# ET6801 register map
Vendor: ETMCU Inc.; File version: v0.0.1
CPU: CM7 r2p1, little endian, MPU, FPU, I-cache, D-cache, ITCM, DTCM, 4 interrupt priority bits
Registers are 32-bit, read-write, reset 0x0 unless marked. A register's access mark holds for its fields unless they carry their own. Offsets are from the block's base; [hi:lo] are bit positions; {n}, {i} and the like mark numbered series.

## SPI0 — Provide an overview of the purpose and functionality of the peripheral: SPI_DWC_ssi
Base 0x4050B000
Same registers: SPI1 0x4050C000, SPI2 0x4050D000, SPI3 0x4050E000
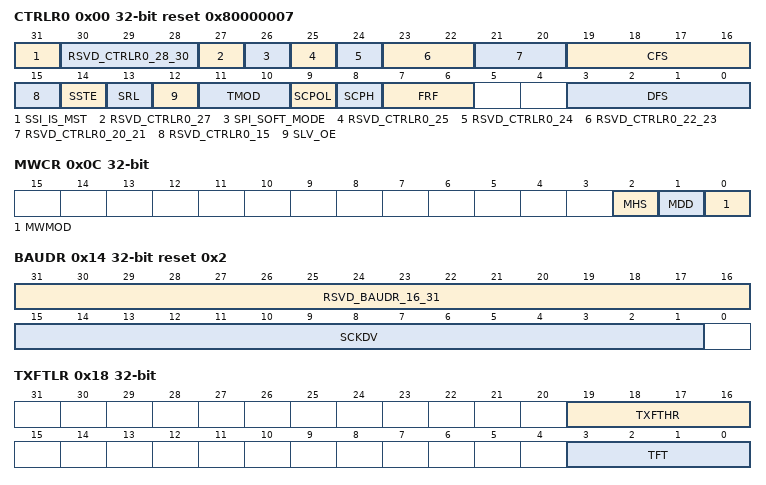
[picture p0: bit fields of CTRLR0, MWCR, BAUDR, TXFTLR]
0x00 CTRLR0 reset 0x80000007
  [31] SSI_IS_MST — This field selects if DWC_ssi is working in Controller or Target mode
  [30:28] RSVD_CTRLR0_28_30 ro — Reserved bits - read as zero
  [27] RSVD_CTRLR0_27 ro — Reserved bits - read as zero
  [26] SPI_SOFT_MODE — 0：ss_n片选信号随状态机变化 1：可使ss_n片选信号不随状态机变化，以满足burst传输模式下数据等待时ss_n片选信号持续有效。spim_soft_mode寄存器复位默认状态为0
  [25] RSVD_CTRLR0_25 ro — Reserved bits - read as zero
  [24] RSVD_CTRLR0_24 ro — Reserved bits - read as zero
  [23:22] RSVD_CTRLR0_22_23 ro — Reserved bits - read as zero
  [21:20] RSVD_CTRLR0_20_21 ro — Reserved bits - read as zero
  [19:16] CFS — Control Frame Size. Selects the length of the control word for the Microwire frame format.
  [15] RSVD_CTRLR0_15 ro — Reserved bits - read as zero
  [14] SSTE — Target Select Toggle Enable. While operating in SPI mode with clock phase (SCPH) set to 0, this register controls the behavior of the chip select line (ss_*_n) between data frames.
  [13] SRL — Shift Register Loop. Used for testing purposes only. When internally active, connects the transmit shift register output to the receive shift register input. Can be used in both serial-target and serial-controller modes. When the DWC_ssi is configured as a target in loopback mode, the ss_in_n and ssi_clk signals must be provided by an external source. In this mode, the target cannot generate these signals because there is nothing to which to loop back.
  [12] SLV_OE — Target Output Enable. Relevant only when the DWC_ssi is configured as a serial-target device. When configured as a serial controller, this bit field has no functionality. This bit enables or disables the setting of the ssi_oe_n output from the DWC_ssi serial target. When SLV_OE = 1, the ssi_oe_n output can never be active. When the ssi_oe_n output controls the tri-state buffer on the txd output from the target, a high impedance state is always present on the target txd output when SLV_OE = 1. This is useful when the controller transmits in broadcast mode (controller transmits data to all target devices). Only one target may respond with data on the controller rxd line. This bit is enabled after reset and must be disabled by software (when broadcast mode is used), if you do not want this device to respond with data. When SSIC_SLV_SPI_MODE is set to 1 and SPI is programmed to work in Enhanced SPI mode, then for correct operation this bit should be programmed to 0.
  [11:10] TMOD — Transfer Mode. Selects the mode of transfer for serial communication. This field does not affect the transfer duplicity. Only indicates whether the receive or transmit data are valid. In transmit-only mode, data received from the external device is not valid and is not stored in the receive FIFO memory; it is overwritten on the next transfer. In receive-only mode, transmitted data are not valid. After the first write to the transmit FIFO, the same word is retransmitted for the duration of the transfer. In transmit-and-receive mode, both transmit and receive data are valid. The transfer continues until the transmit FIFO is empty. Data received from the external device are stored into the receive FIFO memory, where it can be accessed by the host processor.
  [9] SCPOL — Serial Clock Polarity. Valid when the frame format (FRF) is set to Motorola SPI. Used to select the polarity of the inactive serial clock, which is held inactive when the DWC_ssi controller is not actively transferring data on the serial bus.
  [8] SCPH — Serial Clock Phase. Valid when the frame format (FRF) is set to Motorola SPI. The serial clock phase selects the relationship of the serial clock with the chip select signal. When SCPH = 0, data are captured on the first edge of the serial clock. When SCPH = 1, the serial clock starts toggling one cycle after the chip select line is activated, and data are captured on the second edge of the serial clock.
  [7:6] FRF — Frame Format. Selects which serial protocol transfers the data.
  [3:0] DFS — Data Frame Size. Selects the data frame length. When the data frame size is programmed to be less than 16 bits, the receive data is automatically right-justified by the receive logic, with the upper bits of the receive FIFO zero-padded. You must right-justify transmit data before writing into the transmit FIFO. The transmit logic ignores the upper unused bits when transmitting the data. Note: When SSIC_SPI_MODE is set to "Dual", "Quad" or "Octal" mode and SPI_FRF is not set to 2'b00: - DFS value must be a multiple of 2 if SPI_FRF = 01 - DFS value must be multiple of 4 if SPI_FRF = 10 - DFS value must be multiple of 8 if SPI_FRF = 11
0x04 CTRLR1
  [15:0] NDF — Number of Data Frames. When TMOD = 10 or TMOD = 11 , this register field sets the number of data frames to be continuously received by the DWC_ssi. The DWC_ssi continues to receive serial data until the number of data frames received is equal to this register value plus 1, which enables you to receive up to 256 KB of data in a continuous transfer. When SPI_CTRLR0.CLK_STRETCH_EN=1 and TMOD = 01, this register field sets the number of data frames to be continuously transmitted by DWC_ssi. If the Transmit FIFO goes empty in-between, DWC_ssi masks the serial clock (sclk_out) and wait for rest of the data until the programmed amount of frames are transferred successfully. When the DWC_ssi is configured as a serial target, the transfer continues for as long as the target is selected. Therefore, this register serves no purpose and is not present when the DWC_ssi is configured as a serial target.
0x08 SSIENR
  [0] SSIC_EN — SSI Enable. Enables and disables all DWC_ssi operations. When disabled, all serial transfers are halted immediately. Transmit and receive FIFO buffers are cleared when the device is disabled. It is impossible to program some of the DWC_ssi control registers when enabled. When disabled, the ssi sleep output is set (after delay) to inform the system that it is safe to remove the ssi_clk, thus saving power consumption in the system.
0x0C MWCR
  [2] MHS — Microwire Handshaking. Relevant only when the DWC_ssi is configured as a serial-controller device. When configured as a serial target, this bit field has no functionality. Used to enable and disable the busy/ready handshaking interface for the Microwire protocol. When enabled, the DWC_ssi checks for a ready status from the target target, after the transfer of the last data/control bit, before clearing the BUSY status in the SR register.
  [1] MDD — Microwire Control. Defines the direction of the data word when the Microwire serial protocol is used. When this bit is set to 0, the data word is received by the DWC_ssi MacroCell from the external serial device. When this bit is set to 1, the data word is transmitted from the DWC_ssi MacroCell to the external serial device.
  [0] MWMOD — Microwire Transfer Mode. Defines whether the Microwire transfer is sequential or non-sequential. When sequential mode is used, only one control word is needed to transmit or receive a block of data words. When non-sequential mode is used, there must be a control word for each data word that is transmitted or received.
0x10 SER
  [0] SER — Chip Select Enable Flag. Each bit in this register corresponds to a chip select line (ss_x_n) from the DWC_ssi controller. When a bit in this register is set (1), the corresponding chip select line from the controller is activated when a serial transfer begins. It should be noted that setting or clearing bits in this register have no effect on the corresponding chip select outputs until a transfer is started. Before beginning a transfer, you should enable the bit in this register that corresponds to the target device with which the controller wants to communicate. When not operating in broadcast mode, only one bit in this field should be set.
0x14 BAUDR reset 0x2
  [31:16] RSVD_BAUDR_16_31 ro — Reserved bits - read as zero
  [15:1] SCKDV — SSI Clock Divider. The LSB for this field is always set to 0 and is unaffected by a write operation, which ensures an even value is held in this register. If the value is 0, the serial output clock (sclk_out) is disabled. The frequency of the sclk_out is derived from the following equation: Fsclk_out = Fssi_clk/BAUDR where BAUDR is any even value between 2 and 65534 (BAUDR = ). For example: for Fssi_clk = 3.6864MHz and BAUDR =2 Fsclk_out = 3.6864/2 = 1.8432MHz
0x18 TXFTLR
  [19:16] TXFTHR — Transfer start FIFO level. Used to control the level of entries in transmit FIFO above which transfer will start on serial line. This register can be used to ensure that sufficient data is present in transmit FIFO before starting a write operation on serial line. In Internal DMA mode, this field sets the minimum amount of data frames present in the FIFO after which DWC_ssi starts the transfer. This field is valid only for Controller mode of operation.
  [3:0] TFT — Transmit FIFO Threshold. Controls the level of entries (or below) at which the transmit FIFO controller triggers an interrupt. The FIFO depth is configurable in the range 8-256; this register is sized to the number of address bits needed to access the FIFO. If you attempt to set this value greater than or equal to the depth of the FIFO, this field is not written and retains its current value. When the number of transmit FIFO entries is less than or equal to this value, the transmit FIFO empty interrupt is triggered.
0x1C RXFTLR
  [3:0] RFT — Receive FIFO Threshold. Controls the level of entries (or above) at which the receive FIFO controller triggers an interrupt. The FIFO depth is configurable in the range 8-256. This register is sized to the number of address bits needed to access the FIFO. If you attempt to set this value greater than the depth of the FIFO, this field is not written and retains its current value. When the number of receive FIFO entries is greater than or equal to this value + 1, the receive FIFO full interrupt is triggered.
0x20 TXFLR ro
  [4:0] TXTFL — Transmit FIFO Level. Contains the number of valid data entries in the transmit FIFO.
0x24 RXFLR ro
  [4:0] RXTFL — Receive FIFO Level. Contains the number of valid data entries in the receive FIFO.
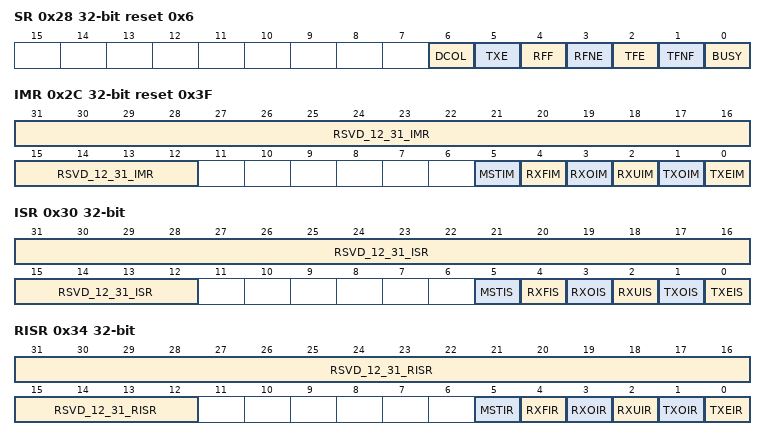
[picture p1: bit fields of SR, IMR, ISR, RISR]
0x28 SR ro reset 0x6
  [6] DCOL — Data Collision Error. Relevant only when the DWC_ssi is configured as a controller device. This bit will be set if ss_in_n input is asserted by other controller, when the DWC_ssi controller is in the middle of the transfer. This informs the processor that the last data transfer was halted before completion. This bit is cleared when read.
  [5] TXE — Transmission Error. Set if the transmit FIFO is empty when a transfer is started. This bit can be set only when the DWC_ssi is configured as a target device. Data from the previous transmission is resent on the txd line. This bit is cleared when read.
  [4] RFF — Receive FIFO Full. When the receive FIFO is completely full, this bit is set. When the receive FIFO contains one or more empty location, this bit is cleared.
  [3] RFNE — Receive FIFO Not Empty. Set when the receive FIFO contains one or more entries and is cleared when the receive FIFO is empty. This bit can be polled by software to completely empty the receive FIFO.
  [2] TFE — Transmit FIFO Empty. When the transmit FIFO is completely empty, this bit is set. When the transmit FIFO contains one or more valid entries, this bit is cleared. This bit field does not request an interrupt.
  [1] TFNF — Transmit FIFO Not Full. Set when the transmit FIFO contains one or more empty locations, and is cleared when the FIFO is full.
  [0] BUSY — SSI Busy Flag. When set, indicates that a serial transfer is in progress; when cleared indicates that the DWC_ssi is idle or disabled.
0x2C IMR reset 0x3F
  [31:12] RSVD_12_31_IMR ro — Reserved bits - read as zero
  [5] MSTIM — Multi-Controller Contention Interrupt Mask. This bit field is not present if the DWC_ssi is configured as a serial-target device.
  [4] RXFIM — Receive FIFO Full Interrupt Mask 0 - ssi_rxf_intr interrupt is masked 1 - ssi_rxf_intr interrupt is not masked
  [3] RXOIM — Receive FIFO Overflow Interrupt Mask
  [2] RXUIM — Receive FIFO Underflow Interrupt Mask
  [1] TXOIM — Transmit FIFO Overflow Interrupt Mask
  [0] TXEIM — Transmit FIFO Empty Interrupt Mask
0x30 ISR ro
  [31:12] RSVD_12_31_ISR — Reserved bits - read as zero
  [5] MSTIS — Multi-Controller Contention Interrupt Status. This bit field is not present if the DWC_ssi is configured as a serial-target device.
  [4] RXFIS — Receive FIFO Full Interrupt Status
  [3] RXOIS — Receive FIFO Overflow Interrupt Status
  [2] RXUIS — Receive FIFO Underflow Interrupt Status
  [1] TXOIS — Transmit FIFO Overflow Interrupt Status
  [0] TXEIS — Transmit FIFO Empty Interrupt Status
0x34 RISR ro
  [31:12] RSVD_12_31_RISR — Reserved bits - read as zero
  [5] MSTIR — Multi-Controller Contention Raw Interrupt Status. This bit field is not present if the DWC_ssi is configured as a serial-target device.
  [4] RXFIR — Receive FIFO Full Raw Interrupt Status
  [3] RXOIR — Receive FIFO Overflow Raw Interrupt Status
  [2] RXUIR — Receive FIFO Underflow Raw Interrupt Status
  [1] TXOIR — Transmit FIFO Overflow Raw Interrupt Status
  [0] TXEIR — Transmit FIFO Empty Raw Interrupt Status
0x38 TXEICR ro
  [0] TXEICR — Clear Transmit FIFO Overflow/Underflow Interrupt. This register reflects the status of the interrupt. A read from this register clears the ssi_txo_intr/ssi_txu_intr interrupt; writing has no effect.
0x3C RXOICR ro
  [0] RXOICR — Clear Receive FIFO Overflow Interrupt. This register reflects the status of the interrupt. A read from this register clears the ssi_rxo_intr interrupt; writing has no effect.
0x40 RXUICR ro
  [0] RXUICR — Clear Receive FIFO Underflow Interrupt. This register reflects the status of the interrupt. A read from this register clears the ssi_rxu_intr interrupt; writing has no effect.
0x44 MSTICR ro
  [0] MSTICR — Clear Multi-Controller Contention Interrupt. This register reflects the status of the interrupt. A read from this register clears the ssi_mst_intr interrupt; writing has no effect.
0x48 ICR ro
  [0] ICR — Clear Interrupts. This register is set if any of the interrupts below are active. A read clears the ssi_done_intr, ssi_axie_intr, ssi_spite_intr, ssi_txo_intr, ssi_txu_intr, ssi_rxu_intr, ssi_xrxo_intr, ssi_rxo_intr and the ssi_mst_intr interrupts. Writing to this register has no effect.
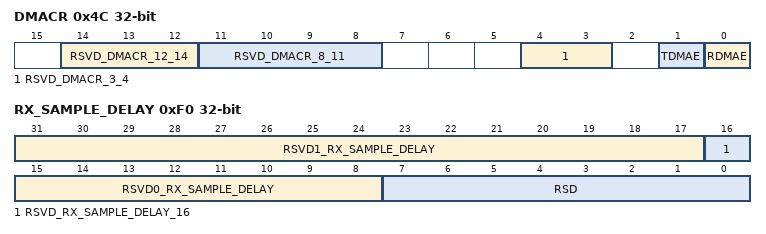
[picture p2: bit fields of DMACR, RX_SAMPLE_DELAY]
0x4C DMACR
  [14:12] RSVD_DMACR_12_14 ro — Reserved bits - read as zero
  [11:8] RSVD_DMACR_8_11 ro — Reserved bits - read as zero
  [4:3] RSVD_DMACR_3_4 ro — Reserved bits - read as zero
  [1] TDMAE — Transmit DMA Enable. This bit enables/disables the transmit FIFO DMA channel.
  [0] RDMAE — Receive DMA Enable. This bit enables/disables the receive FIFO DMA channel.
0x50 DMATDLR
  [3:0] DMATDL — Transmit Data Level. This bit field controls the level at which a DMA request is made by the transmit logic. It is equal to the watermark level; that is, the dma_tx_req signal is generated when the number of valid data entries in the transmit FIFO is equal to or below this field value, and TDMAE = 1.
0x54 DMARDLR
  [3:0] DMARDL — Receive Data Level. This bit field controls the level at which a DMA request is made by the receive logic. The watermark level = DMARDL+1; that is, dma_rx_req is generated when the number of valid data entries in the receive FIFO is equal to or above this field value + 1, and RDMAE=1.
0x58 IDR ro reset 0xFFFFFFFF
  [31:0] IDCODE — Identification code. The register contains the identification code of the peripheral, which is written into the register at configuration time using CoreConsultant.
0x5C SSIC_VERSION_ID ro reset 0x3230312A
  [31:0] SSIC_COMP_VERSION — Contains the hex representation of the Synopsys component version. Consists of ASCII value for each number in the version, followed by *. For example 31_30_33_2A represents the version 1.03*.
{0x60+4i} DR{i} (i=0..35)
  [31:0] DR — Data Register. When writing to this register, you must right-justify the data. Read data are automatically right-justified. Read = Receive FIFO buffer Write = Transmit FIFO buffer.
0xF0 RX_SAMPLE_DELAY
  [31:17] RSVD1_RX_SAMPLE_DELAY ro — Reserved bits - read as zero
  [16] RSVD_RX_SAMPLE_DELAY_16 ro — Reserved bits - read as zero
  [15:8] RSVD0_RX_SAMPLE_DELAY ro — Reserved bits - read as zero
  [7:0] RSD — Receive Data (rxd) Sample Delay. This register is used to delay the sample of the rxd input port. Each value represents a single ssi_clk delay on the sample of rxd. Note; If this register is programmed with a value that exceeds the depth of the internal shift registers (SSIC_RX_DLY_SR_DEPTH) zero delay will be applied to the rxd sample.
